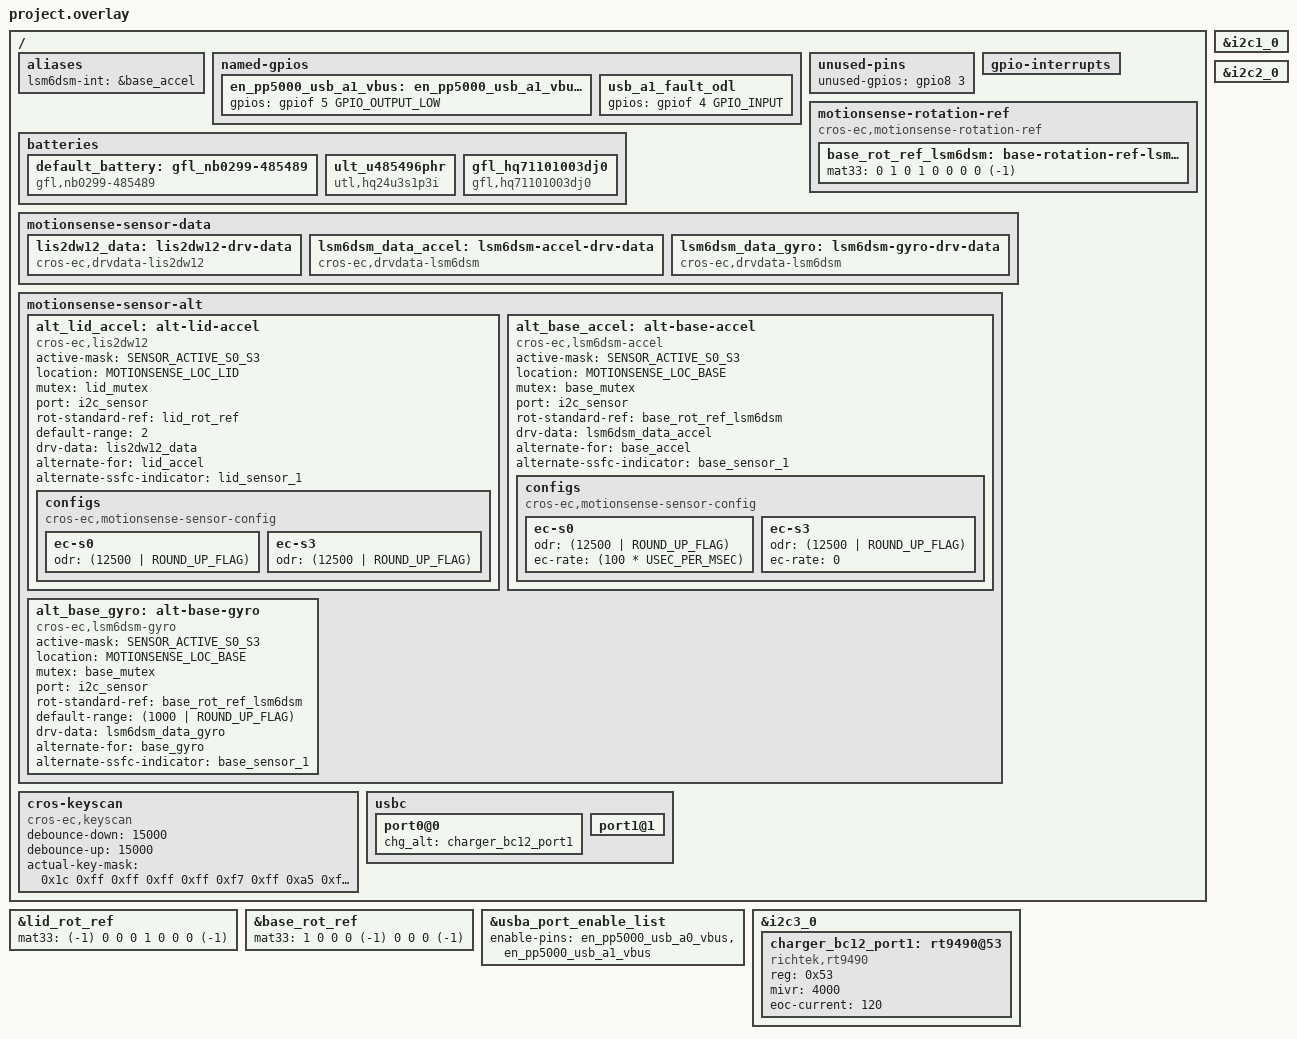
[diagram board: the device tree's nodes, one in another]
/* Copyright 2023 The ChromiumOS Authors
 * Use of this source code is governed by a BSD-style license that can be
 * found in the LICENSE file.
 */

/* Corsola program common DTS includes */

#include "../common.dtsi"
#include "../power_signal.dtsi"
#include "../usba.dtsi"
#include "../npcx_adc.dtsi"
#include "../npcx_gpio.dtsi"
#include "../npcx_host_interface.dtsi"
#include "../npcx_i2c.dtsi"
#include "../npcx_interrupts.dtsi"
#include "../npcx_keyboard.dtsi"
#include "../npcx_motionsense.dtsi"
#include "../npcx_usbc.dtsi"
#include "../npcx_default_gpio_pinctrl.dtsi"
#include <dt-bindings/battery.h>

/* Projrect level DTS shared with tests */
#include "./cbi.dtsi"
#include "./interrupts.dtsi"
#include "./led.dtsi"
#include "./temps.dtsi"

/* board override */
/ {
	aliases {
		/*
		 * motion sense's <>_INT_EVENT is handled
		 * by alias. Using the alias, each driver creates
		 * its own <>_INT_EVENT.
		 */
		lsm6dsm-int = &base_accel;
	};

	named-gpios {
		/delete-node/ usb_c0_bc12_int_odl;

 		en_pp5000_usb_a1_vbus: en_pp5000_usb_a1_vbus_x {
			gpios = <&gpiof 5 GPIO_OUTPUT_LOW>;
		};
		usb_a1_fault_odl {
			gpios = <&gpiof 4 GPIO_INPUT>;
		};
	};

	unused-pins {
		unused-gpios =
			<&gpio8 3 0>;
	};

	gpio-interrupts {
		/delete-node/ usb_c0_bc12;
	};

	batteries {
		default_battery: gfl_nb0299-485489 {
			compatible = "gfl,nb0299-485489", "battery-smart";
		};
		ult_u485496phr {
			compatible = "utl,hq24u3s1p3i", "battery-smart";
		};
		gfl_hq71101003dj0 {
			compatible = "gfl,hq71101003dj0", "battery-smart";
		};
	};


	/* Rotation matrix used by drivers. */
	motionsense-rotation-ref {
		compatible = "cros-ec,motionsense-rotation-ref";
		base_rot_ref_lsm6dsm: base-rotation-ref-lsm6dsm {
			mat33 = <0 1 0
				 1 0 0
				 0 0 (-1)>;
		};
	};

	/*
	 * Driver specific data. A driver-specific data can be shared with
	 * different motion sensors while they are using the same driver.
	 *
	 * If a node's compatible starts with "cros-ec,accelgyro-", it is for
	 * a common structure defined in accelgyro.h.
	 * e.g) compatible = "cros-ec,accelgyro-als-drv-data" is for
	 * "struct als_drv_data_t" in accelgyro.h
	 */
	motionsense-sensor-data {
		lis2dw12_data: lis2dw12-drv-data {
			compatible = "cros-ec,drvdata-lis2dw12";
			status = "okay";
		};
		lsm6dsm_data_accel: lsm6dsm-accel-drv-data {
			compatible = "cros-ec,drvdata-lsm6dsm";
			status = "okay";
		};
		lsm6dsm_data_gyro: lsm6dsm-gyro-drv-data {
			compatible = "cros-ec,drvdata-lsm6dsm";
			status = "okay";
		};
	};

	motionsense-sensor-alt {
		alt_lid_accel: alt-lid-accel {
			compatible = "cros-ec,lis2dw12";
			status = "okay";

			active-mask = "SENSOR_ACTIVE_S0_S3";
			location = "MOTIONSENSE_LOC_LID";
			mutex = <&lid_mutex>;
			port = <&i2c_sensor>;
			rot-standard-ref = <&lid_rot_ref>;
			default-range = <2>;
			drv-data = <&lis2dw12_data>;
			alternate-for = <&lid_accel>;
			alternate-ssfc-indicator = <&lid_sensor_1>;
			configs {
				compatible =
					"cros-ec,motionsense-sensor-config";
				ec-s0 {
					odr = <(12500 | ROUND_UP_FLAG)>;
				};
				ec-s3 {
					odr = <(12500 | ROUND_UP_FLAG)>;
				};
			};
		};

		alt_base_accel: alt-base-accel {
			compatible = "cros-ec,lsm6dsm-accel";
			status = "okay";

			active-mask = "SENSOR_ACTIVE_S0_S3";
			location = "MOTIONSENSE_LOC_BASE";
			mutex = <&base_mutex>;
			port = <&i2c_sensor>;
			rot-standard-ref = <&base_rot_ref_lsm6dsm>;
			drv-data = <&lsm6dsm_data_accel>;
			alternate-for = <&base_accel>;
			alternate-ssfc-indicator = <&base_sensor_1>;
			configs {
				compatible =
					"cros-ec,motionsense-sensor-config";
				ec-s0 {
					odr = <(12500 | ROUND_UP_FLAG)>;
					ec-rate = <(100 * USEC_PER_MSEC)>;
				};
				ec-s3 {
					odr = <(12500 | ROUND_UP_FLAG)>;
					ec-rate = <0>;
				};
			};
		};

		alt_base_gyro: alt-base-gyro {
			compatible = "cros-ec,lsm6dsm-gyro";
			status = "okay";

			active-mask = "SENSOR_ACTIVE_S0_S3";
			location = "MOTIONSENSE_LOC_BASE";
			mutex = <&base_mutex>;
			port = <&i2c_sensor>;
			rot-standard-ref = <&base_rot_ref_lsm6dsm>;
			default-range = <(1000 | ROUND_UP_FLAG)>; /* dps */
			drv-data = <&lsm6dsm_data_gyro>;
			alternate-for = <&base_gyro>;
			alternate-ssfc-indicator = <&base_sensor_1>;
		};
	};

	cros-keyscan {
		compatible = "cros-ec,keyscan";

		debounce-down = <15000>;
		debounce-up = <15000>;

		actual-key-mask = <
			0x1c	/* C0 */
			0xff	/* C1 */
			0xff	/* C2 */
			0xff	/* C3 */
			0xff	/* C4 */
			0xf7	/* C5 */
			0xff	/* C6 */
			0xa5	/* C7 */
			0xff	/* C8 */
			0xff	/* C9 */
			0x55	/* C10 */
			0xfa	/* C11 */
			0xcb	/* C12 */
			>;
	};

	usbc {
		port0@0 {
			/delete-property/ bc12;
			chg_alt = <&charger_bc12_port1>;
		};

		port1@1 {
			/delete-property/ bc12;
		};
	};
};

/* inherit the rot_ref from Kingler and overwrite it */
&lid_rot_ref {
	mat33 = <(-1) 0 0
		0 1 0
		0 0 (-1)>;
};

&base_rot_ref {
	mat33 = <1 0 0
		0 (-1) 0
		0 0 (-1)>;
};

/* ponyta usba port enable config */
&usba_port_enable_list {
	enable-pins = <&en_pp5000_usb_a0_vbus
		       &en_pp5000_usb_a1_vbus>;
};

&i2c1_0 {
	/delete-node/ pi3usb9201@5f;
};

&i2c2_0 {
	/delete-node/ rt1718s-bc12@40;
};

&i2c3_0 {
	charger_bc12_port1: rt9490@53 {
		compatible = "richtek,rt9490";
		status = "okay";
		reg = <0x53>;
		mivr = <4000>;
		eoc-current = <120>;
	};
};
